# AST2600 register map
File version: 1.1
CPU: CM3 r1p0, little endian, no MPU, no FPU, 3 interrupt priority bits
Registers are 32-bit, read-write, reset 0x0 unless marked. A register's access mark holds for its fields unless they carry their own. Offsets are from the block's base; lines under a group give offsets from that group; [hi:lo] are bit positions; {n}, {i} and the like mark numbered series; 'fields as' and 'values as' point back to an identical list; <NAME> marks a mode.

## Memory map
0xE000E010 SYSTICK size 0x10 — SysTick Timer
0xE000E100 NVIC size 0x4F0 — Nested Vectored Interrupt Controller
0xE000ED00 SCB size 0x90 — System Control Block
0xE000EDF0 DCB size 0x10 — Debug Control Block
0xE000EF00 SIG size 0x4 — Software Interrupt Generation

## DCB — Debug Control Block
Base 0xE000EDF0
0x00 Debug Halting Control and Status Register — Controls halting debug
  [25] S_RESET_ST — Indicates whether the processor has been reset since the last read of DHCSR
  [24] S_RETIRE_ST — Set to 1 every time the processor retires one or more instructions
  [19] S_LOCKUP — Indicates whether the processor is locked up because of an unrecoverable exception
  [18] S_SLEEP — Indicates whether the processor is sleeping
  [17] S_HALT — Indicates whether the processor is in Debug state
  [31:16] DBGKEY — Debug key
  [16] S_REGRDY — A handshake flag for transfers through the DCRDR
  [5] C_SNAPSTALL — Allow imprecise entry to Debug state
  [3] C_MASKINTS — When debug is enabled, the debugger can write to this bit to mask PendSV, SysTick and external configurable interrupts
  [2] C_STEP — Processor step bit
  [1] C_HALT — Processor halt bit
  [0] C_DEBUGEN — Halting debug enable bit
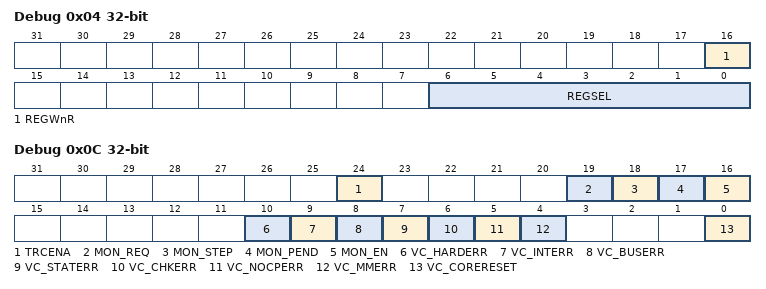
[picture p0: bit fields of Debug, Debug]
0x04 Debug Core Register Selector Register wo — provides debug access to the ARM core registers, special-purpose registers, and Floating-point extension regi
  [16] REGWnR — Specifies the access type for the transfer
  [6:0] REGSEL — Specifies the ARM core register, special-purpose register, or Floating-point extension register, to transfer
0x08 Debug Core Register Data Register — provides debug access to the ARM core registers, special-purpose registers, and Floating-point extensio
  [31:0] DBGTMP — Data temporary cache, for reading and writing the ARM core registers, special-purpose registers, and Floating-point extension registers
0x0C Debug Exception and Monitor Control Register — Manages vector catch behavior and DebugMonitor handling when debugging
  [24] TRCENA — Global enable for all DWT and ITM features
  [19] MON_REQ — DebugMonitor semaphore bit
  [18] MON_STEP — When MON_EN is set to 0, this feature is disabled and the processor ignores MON_STEP
  [17] MON_PEND — Sets or clears the pending state of the DebugMonitor exception
  [16] MON_EN — Enable the DebugMonitor exception
  [10] VC_HARDERR — Enable halting debug trap on a HardFault exception
  [9] VC_INTERR — Enable halting debug trap on a fault occurring during exception entry or exception return
  [8] VC_BUSERR — Enable halting debug trap on a BusFault exception
  [7] VC_STATERR — Enable halting debug trap on a UsageFault exception caused by a state information error, for example an Undefined Instruction exception
  [6] VC_CHKERR — Enable halting debug trap on a UsageFault exception caused by a checking error, for example an alignment check error
  [5] VC_NOCPERR — Enable halting debug trap on a UsageFault caused by an access to a Coprocessor
  [4] VC_MMERR — Enable halting debug trap on a MemManage exception
  [0] VC_CORERESET — Enable Reset Vector Catch

## SIG — Software Interrupt Generation
Base 0xE000EF00
0x00 Software Triggered Interrupt Register wo — Provides a mechanism for software to generate an interrupt
  [8:0] INTID — Indicates the interrupt to be triggered

## SYSTICK — SysTick Timer
Base 0xE000E010
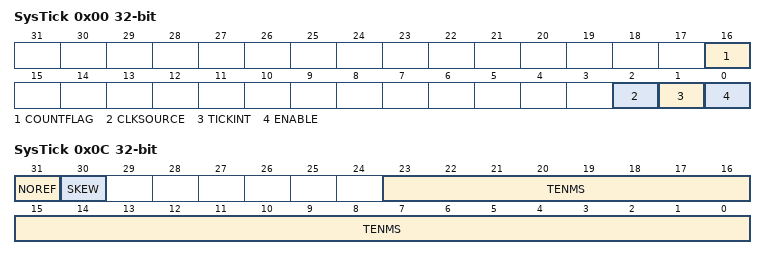
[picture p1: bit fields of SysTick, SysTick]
0x00 SysTick Control and Status Register — Controls the system timer and provides status data
  [16] COUNTFLAG — Indicates whether the counter has counted to 0 since the last read of this register
  [2] CLKSOURCE — Indicates the SysTick clock source
  [1] TICKINT — Indicates whether counting to 0 causes the status of the SysTick exception to change to pending
  [0] ENABLE — Indicates the enabled status of the SysTick counter
0x04 SysTick Reload Value Register — Holds the reload value of the SYST_CVR
  [23:0] RELOAD — The value to load into the SYST_CVR when the counter reaches 0
0x08 SysTick Current Value Register — Reads or clears the current counter value
  [31:0] CURRENT — Current counter value
0x0C SysTick Calibration value Register ro — Reads the calibration value and parameters for SysTick
  [31] NOREF — Indicates whether the IMPLEMENTATION DEFINED reference clock is implemented
  [30] SKEW — Indicates whether the 10ms calibration value is exact
  [23:0] TENMS — Optionally, holds a reload value to be used for 10ms (100Hz) timing, subject to system clock skew errors
